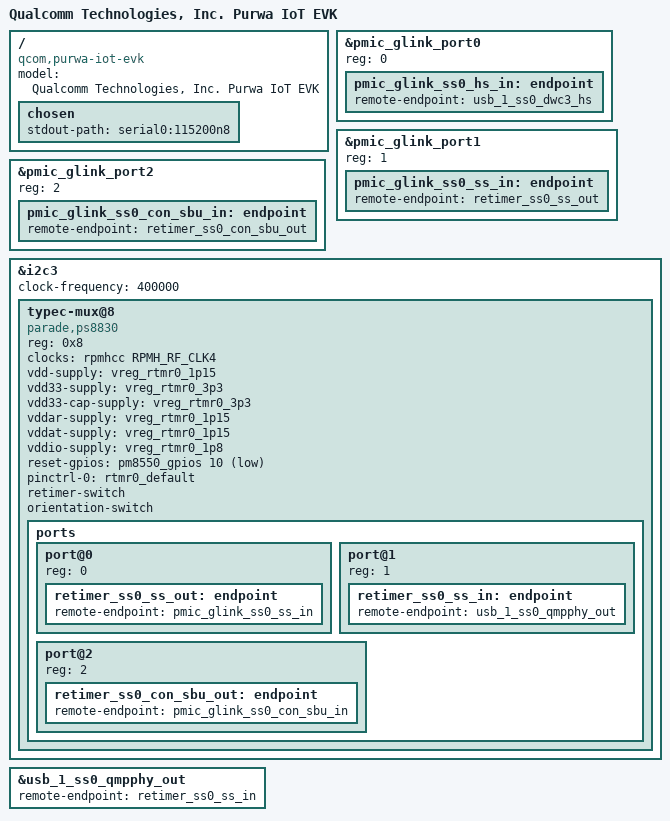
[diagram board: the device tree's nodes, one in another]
// SPDX-License-Identifier: BSD-3-Clause
/*
 * Copyright (c) Qualcomm Technologies, Inc. and/or its subsidiaries.
 */

/dts-v1/;

#include "purwa-iot-som.dtsi"
#include "iq-x-iot-evk.dtsi"

/ {
	model = "Qualcomm Technologies, Inc. Purwa IoT EVK";
	compatible = "qcom,purwa-iot-evk",
		     "qcom,purwa-iot-som",
		     "qcom,x1p42100";

	chosen {
		stdout-path = "serial0:115200n8";
	};
};

&pmic_glink_port0 {
	reg = <0>;
	pmic_glink_ss0_hs_in: endpoint {
		remote-endpoint = <&usb_1_ss0_dwc3_hs>;
	};
};
&pmic_glink_port1 {
	reg = <1>;
	pmic_glink_ss0_ss_in: endpoint {
		remote-endpoint = <&retimer_ss0_ss_out>;
	};
};
&pmic_glink_port2 {
	reg = <2>;
	pmic_glink_ss0_con_sbu_in: endpoint {
		remote-endpoint = <&retimer_ss0_con_sbu_out>;
	};
};

&i2c3 {
	clock-frequency = <400000>;

	status = "okay";

	typec-mux@8 {
		compatible = "parade,ps8830";
		reg = <0x8>;

		clocks = <&rpmhcc RPMH_RF_CLK4>;

		vdd-supply = <&vreg_rtmr0_1p15>;
		vdd33-supply = <&vreg_rtmr0_3p3>;
		vdd33-cap-supply = <&vreg_rtmr0_3p3>;
		vddar-supply = <&vreg_rtmr0_1p15>;
		vddat-supply = <&vreg_rtmr0_1p15>;
		vddio-supply = <&vreg_rtmr0_1p8>;

		reset-gpios = <&pm8550_gpios 10 GPIO_ACTIVE_LOW>;

		pinctrl-0 = <&rtmr0_default>;
		pinctrl-names = "default";

		retimer-switch;
		orientation-switch;

		ports {
			#address-cells = <1>;
			#size-cells = <0>;

			port@0 {
				reg = <0>;

				retimer_ss0_ss_out: endpoint {
					remote-endpoint = <&pmic_glink_ss0_ss_in>;
				};
			};

			port@1 {
				reg = <1>;

				retimer_ss0_ss_in: endpoint {
					remote-endpoint = <&usb_1_ss0_qmpphy_out>;
				};
			};

			port@2 {
				reg = <2>;

				retimer_ss0_con_sbu_out: endpoint {
					remote-endpoint = <&pmic_glink_ss0_con_sbu_in>;
				};
			};
		};
	};
};

&usb_1_ss0_qmpphy_out {
	remote-endpoint = <&retimer_ss0_ss_in>;
};
